# CY8C4245PVI_482 register map
File version: 0.1
PSoC 4200
Registers are 32-bit, read-write, no defined reset value unless marked. A register's access mark holds for its fields unless they carry their own. Offsets are from the block's base; lines under a group give offsets from that group; [hi:lo] are bit positions; {n}, {i} and the like mark numbered series; 'fields as' and 'values as' point back to an identical list; <NAME> marks a mode.

## Memory map
0x00000000 TX_SEND
0x00000000 PWM_MOT
0x00000000 UART — Serial Communication Block
0x00000000 ADC — Sequencing SAR ADC
0x400F0060 QDEC_FAULT
0x400F0061 QDEC_DIR
0x400F0070 RESET_FAULT

## QDEC_FAULT
Base 0x400F0060
0x00 QDEC_FAULT_STATUS_REG 8-bit
0x20 QDEC_FAULT_MASK_REG 8-bit
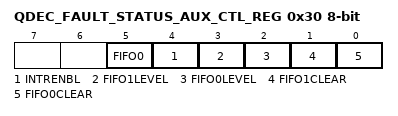
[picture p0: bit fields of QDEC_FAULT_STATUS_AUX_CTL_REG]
0x30 QDEC_FAULT_STATUS_AUX_CTL_REG 8-bit
  [5] FIFO0 — FIFO0 clear
    1=ENABLED (Enable counter); 0=DISABLED (Disable counter)
  [4] INTRENBL — Enables or disables the Interrupt
    1=ENABLED (Interrupt enabled); 0=DISABLED (Interrupt disabled)
  [3] FIFO1LEVEL — FIFO level
    1=ENABLED (FIFO LVL: input mode: FIFO at least 1/2 empty; output mode: FIFO at least 1/2 full); 0=DISABLED (FIFO LVL: input mode: FIFO not full; output mode: FIFO not empty)
  [2] FIFO0LEVEL — FIFO level
    values as FIFO1LEVEL
  [1] FIFO1CLEAR — FIFO clear
    1=ENABLED (Clear FIFO state); 0=DISABLED (Normal FIFO operation)
  [0] FIFO0CLEAR — FIFO clear
    values as FIFO1CLEAR

## QDEC_DIR
Base 0x400F0061
Registers as QDEC_FAULT (with QDEC_FAULT read as QDEC_DIR).

## TX_SEND
Base 0x00000000
0x40050108 COUNTER — Current counter value
0x4005010C CC — Compare / capture value
0x40050110 CC_BUF — Compare / capture buffer value
0x40050114 PERIOD — Period value
0x40050118 PERIOD_BUF — Period buffer value

## RESET_FAULT
Base 0x400F0070
0x00 RESET_FAULT_CONTROL_REG 8-bit

## PWM_MOT
Base 0x00000000
0x40050148 COUNTER — Current counter value
0x4005014C CC — Compare / capture value
0x40050150 CC_BUF — Compare / capture buffer value
0x40050154 PERIOD — Period value
0x40050158 PERIOD_BUF — Period buffer value
